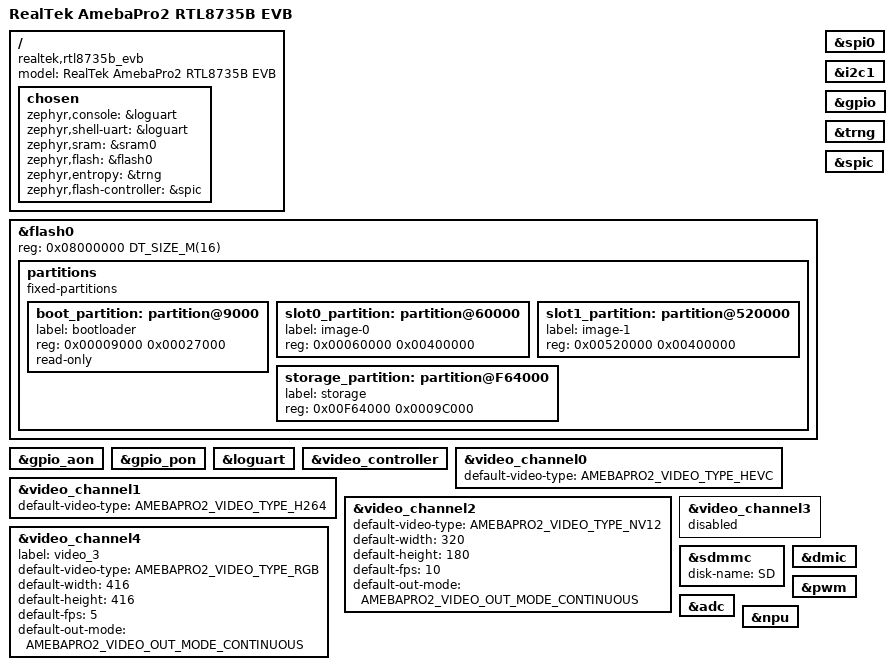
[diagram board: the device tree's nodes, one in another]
/*
 * Copyright (c) 2024 Realtek Semiconductor Corp.
 *
 * SPDX-License-Identifier: Apache-2.0
 */

/dts-v1/;

#include <realtek/amebapro2/amebapro2.dtsi>
#include "rtl8735b_evb-pinctrl.dtsi"
#include <dt-bindings/video/amebapro2_video.h>

/ {
	model = "RealTek AmebaPro2 RTL8735B EVB";
	compatible = "realtek,rtl8735b_evb";

	chosen {
		zephyr,console = &loguart;
		zephyr,shell-uart = &loguart;
		zephyr,sram = &sram0;
		zephyr,flash = &flash0;
		zephyr,entropy = &trng;
		zephyr,flash-controller = &spic;
	};
};

/* 16MB flash */
&flash0 {
	reg = <0x08000000 DT_SIZE_M(16)>;

	partitions {
		compatible = "fixed-partitions";
		#address-cells = <1>;
		#size-cells = <1>;

		boot_partition: partition@9000 {
			label = "bootloader";
			reg = <0x00009000 0x00027000>;
			read-only;
		};

		slot0_partition: partition@60000 {
			label = "image-0";
			reg = <0x00060000 0x00400000>;
		};

		slot1_partition: partition@520000 {
			label = "image-1";
			reg = <0x00520000 0x00400000>;
		};

		storage_partition: partition@F64000 {
			label = "storage";
			reg = <0x00F64000 0x0009C000>;
		};
	};
};

&spi0 {
	status = "okay";
};

&i2c1 {
	status = "okay";
};

&gpio_aon {
	status = "okay";
};

&gpio_pon {
	status = "okay";
};

&gpio {
	status = "okay";
};

&trng {
	status = "okay";
};

&loguart {
	status = "okay";
};

&spic {
	status = "okay";
};

&video_controller {
	status = "okay";
};

&video_channel0 {
	status = "okay";
	default-video-type = <AMEBAPRO2_VIDEO_TYPE_HEVC>;
};

&video_channel1 {
	status = "okay";
	default-video-type = <AMEBAPRO2_VIDEO_TYPE_H264>;
};

&video_channel2 {
	status = "okay";
	default-video-type = <AMEBAPRO2_VIDEO_TYPE_NV12>;
	default-width = <320>;
	default-height = <180>;
	default-fps = <10>;
	default-out-mode = <AMEBAPRO2_VIDEO_OUT_MODE_CONTINUOUS>;
};

&video_channel3 {
	status = "disabled";
};

/* Logical video_3 uses physical CH4 because RGB output is only supported on CH4. */
&video_channel4 {
	status = "okay";
	label = "video_3";
	default-video-type = <AMEBAPRO2_VIDEO_TYPE_RGB>;
	default-width = <416>;
	default-height = <416>;
	default-fps = <5>;
	default-out-mode = <AMEBAPRO2_VIDEO_OUT_MODE_CONTINUOUS>;
};

&sdmmc {
	status = "okay";
	disk-name = "SD";
};

&dmic {
	status = "okay";
};

&pwm {
	status = "okay";
};

&adc {
	status = "okay";
};

&npu {
	status = "okay";
};
